AUTOSAR XML (schema 4-2-2)
package /ARRoot
  sender receiver interface MyInterface
    data MyInterface: type=uint8
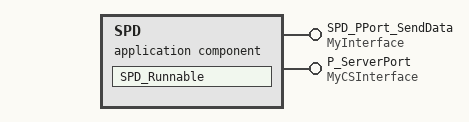
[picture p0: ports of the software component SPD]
  application sw component type SPD
    provide port SPD_PPort_SendData: nonqueued-sender-com-spec=data-element=MyInterface, provided-interface=MyInterface
    provide port P_ServerPort: provided-interface=MyCSInterface
    swc-internal-behavior:
      events:
        timing-event={start-on-event=SPD_Runnable, period=0.1}
        operation-invoked-event=P_ServerPort.Operation1
        operation-invoked-event=P_ServerPort.Operation2
      runnable SPD_Runnable: data-send-points=variable-access=accessed-variable=SPD_PPort_SendData
  swc-implementation behavior=/ARRoot/SPD/:
    code-descriptors:
      code Code
    resource consumption ResourceConsumption
  client server interface MyCSInterface
    operation Operation1: possible-error=E_OK
      arg Arg1: type=uint8, direction=IN
    operation Operation2: possible-error=E_OK
      arg Arg2: type=uint8, direction=OUT
    error E_OK
